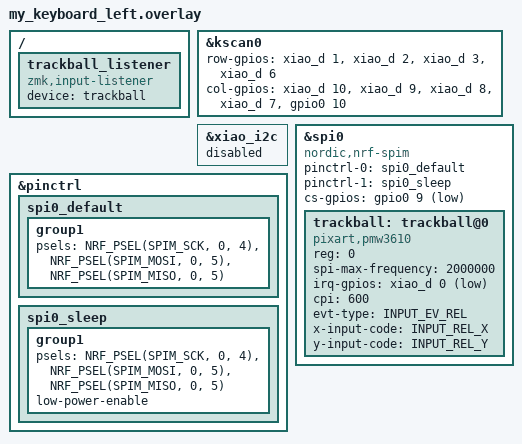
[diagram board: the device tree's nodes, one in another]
#include "my_keyboard.dtsi"
#include <zephyr/dt-bindings/input/input-event-codes.h>

/*
 * 左手 (XIAO nRF52840) ピンアサイン ※旧基板
 *   D1/D2/D3/D6 : row0〜row3
 *   D10/D9/D8/D7/NFC2 : col0〜col4   (col5 は SWDIO のため未使用)
 *   D4 (P0.04)  : PMW3610 SCLK
 *   D5 (P0.05)  : PMW3610 SDIO (MOSI/MISO 兼用の3線SPI)
 *   NFC1 (P0.09): PMW3610 nCS
 *   D0 (P0.02)  : PMW3610 MOTION
 */

&kscan0 {
    row-gpios
        = <&xiao_d 1 GPIO_ACTIVE_HIGH>
        , <&xiao_d 2 GPIO_ACTIVE_HIGH>
        , <&xiao_d 3 GPIO_ACTIVE_HIGH>
        , <&xiao_d 6 GPIO_ACTIVE_HIGH>
        ;
    col-gpios
        = <&xiao_d 10 (GPIO_ACTIVE_HIGH | GPIO_PULL_DOWN)>
        , <&xiao_d 9  (GPIO_ACTIVE_HIGH | GPIO_PULL_DOWN)>
        , <&xiao_d 8  (GPIO_ACTIVE_HIGH | GPIO_PULL_DOWN)>
        , <&xiao_d 7  (GPIO_ACTIVE_HIGH | GPIO_PULL_DOWN)>
        , <&gpio0 10  (GPIO_ACTIVE_HIGH | GPIO_PULL_DOWN)>
        ;
};

/* D4/D5 は標準で I2C になっているので止める（UART はログ機能が使うので残す） */
&xiao_i2c    { status = "disabled"; };

&pinctrl {
    spi0_default: spi0_default {
        group1 {
            psels = <NRF_PSEL(SPIM_SCK,  0, 4)>,
                    <NRF_PSEL(SPIM_MOSI, 0, 5)>,
                    <NRF_PSEL(SPIM_MISO, 0, 5)>;
        };
    };
    spi0_sleep: spi0_sleep {
        group1 {
            psels = <NRF_PSEL(SPIM_SCK,  0, 4)>,
                    <NRF_PSEL(SPIM_MOSI, 0, 5)>,
                    <NRF_PSEL(SPIM_MISO, 0, 5)>;
            low-power-enable;
        };
    };
};

&spi0 {
    status = "okay";
    compatible = "nordic,nrf-spim";
    pinctrl-0 = <&spi0_default>;
    pinctrl-1 = <&spi0_sleep>;
    pinctrl-names = "default", "sleep";
    cs-gpios = <&gpio0 9 GPIO_ACTIVE_LOW>;          /* NFC1 */

    trackball: trackball@0 {
        status = "okay";
        compatible = "pixart,pmw3610";
        reg = <0>;
        spi-max-frequency = <2000000>;
        irq-gpios = <&xiao_d 0 (GPIO_ACTIVE_LOW | GPIO_PULL_UP)>;   /* D0 */
        cpi = <600>;
        evt-type = <INPUT_EV_REL>;
        x-input-code = <INPUT_REL_X>;
        y-input-code = <INPUT_REL_Y>;
        /* 向きが合わないときはここを有効化 */
        // swap-xy;
        // invert-x;
        // invert-y;
    };
};

/ {
    trackball_listener {
        compatible = "zmk,input-listener";
        device = <&trackball>;
    };
};
